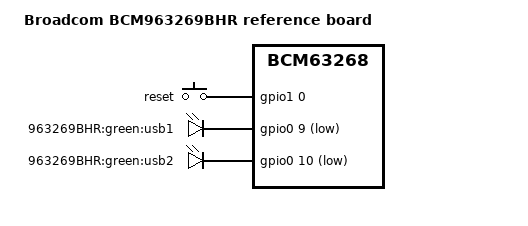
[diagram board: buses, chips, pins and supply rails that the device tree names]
/dts-v1/;

#include "bcm63268.dtsi"

#include <dt-bindings/input/input.h>

/ {
	model = "Broadcom BCM963269BHR reference board";
	compatible = "brcm,bcm963269bhr", "brcm,bcm63268";

	chosen {
		bootargs = "root=/dev/mtdblock2 rootfstype=squashfs,jffs2 noinitrd console=ttyS0,115200";
	};

	gpio-keys-polled {
		compatible = "gpio-keys-polled";
		#address-cells = <1>;
		#size-cells = <0>;
		poll-interval = <20>;
		debounce-interval = <60>;

		reset {
			label = "reset";
			gpios = <&gpio1 0 0>;
			linux,code = <KEY_RESTART>;
		};
        };

	gpio-leds {
		compatible = "gpio-leds";

		usb1 {
			label = "963269BHR:green:usb1";
			gpios = <&gpio0 9 1>;
		};

		usb2 {
			label = "963269BHR:green:usb2";
			gpios = <&gpio0 10 1>;
		};
	};
};
